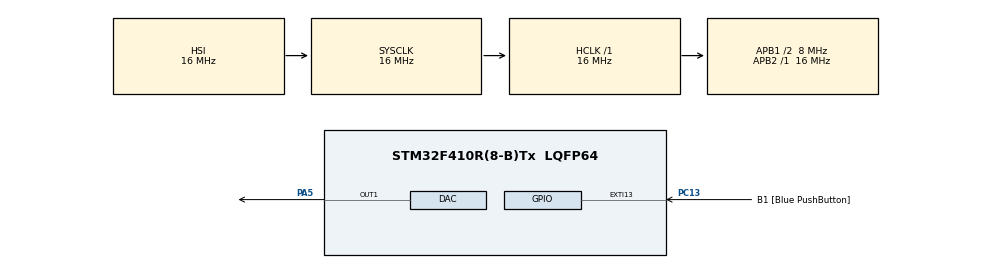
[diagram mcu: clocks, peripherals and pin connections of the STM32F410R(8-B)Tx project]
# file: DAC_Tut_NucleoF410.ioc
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DAC.DAC_Trigger=DAC_TRIGGER_T6_TRGO
Dma.DAC1.0.Direction=DMA_MEMORY_TO_PERIPH
Dma.DAC1.0.FIFOMode=DMA_FIFOMODE_DISABLE
Dma.DAC1.0.Instance=DMA1_Stream5
Dma.DAC1.0.MemDataAlignment=DMA_MDATAALIGN_HALFWORD
Dma.DAC1.0.MemInc=DMA_MINC_ENABLE
Dma.DAC1.0.Mode=DMA_CIRCULAR
Dma.DAC1.0.PeriphDataAlignment=DMA_PDATAALIGN_HALFWORD
Dma.DAC1.0.PeriphInc=DMA_PINC_DISABLE
Dma.DAC1.0.Priority=DMA_PRIORITY_LOW
Dma.Request0=DAC1
Mcu.Family=STM32F4
Mcu.Name=STM32F410R(8-B)Tx
Mcu.Package=LQFP64
NVIC.DMA1_Stream5_IRQn=true\:0\:0\:false\:false\:true\:false\:true\:true
NVIC.PriorityGroup=NVIC_PRIORITYGROUP_0
NVIC.TIM6_DAC_IRQn=true\:0\:0\:false\:false\:true\:true\:true\:true
PA13.GPIO_Label=TMS
PA13.Mode=Serial_Wire
PA13.Signal=SYS_JTMS-SWDIO
PA14.GPIO_Label=TCK
PA14.Mode=Serial_Wire
PA14.Signal=SYS_JTCK-SWCLK
PA2.GPIO_Label=USART_TX
PA2.Signal=USART2_TX
PA3.GPIO_Label=USART_RX
PA3.Signal=USART2_RX
PA5.Signal=COMP_DAC1_group
PB3.GPIO_Label=SWO
PB3.Signal=SYS_JTDO-SWO
PC13-ANTI_TAMP.GPIO_Label=B1 [Blue PushButton]
PC13-ANTI_TAMP.GPIO_ModeDefaultEXTI=GPIO_MODE_IT_FALLING
PC13-ANTI_TAMP.Signal=GPXTI13
PC14-OSC32_IN.Mode=LSE-External-Oscillator
PC14-OSC32_IN.Signal=RCC_OSC32_IN
PC15-OSC32_OUT.Mode=LSE-External-Oscillator
PC15-OSC32_OUT.Signal=RCC_OSC32_OUT
PH0\ -\ OSC_IN.Mode=HSE-External-Clock-Source
PH0\ -\ OSC_IN.Signal=RCC_OSC_IN
PH1\ -\ OSC_OUT.Mode=HSE-External-Clock-Source
PH1\ -\ OSC_OUT.Signal=RCC_OSC_OUT
ProjectManager.HeapSize=0x200
ProjectManager.StackSize=0x400
ProjectManager.TargetToolchain=STM32CubeIDE
RCC.48MHZClocksFreq_Value=336000000
RCC.AHBFreq_Value=16000000
RCC.APB1CLKDivider=RCC_HCLK_DIV2
RCC.APB1Freq_Value=8000000
RCC.APB1TimFreq_Value=16000000
RCC.APB2Freq_Value=16000000
RCC.APB2TimFreq_Value=16000000
RCC.CortexFreq_Value=16000000
RCC.FLatency-AdvancedSettings=FLASH_LATENCY_0
RCC.HCLKFreq_Value=16000000
RCC.HSE_VALUE=8000000
RCC.HSI_VALUE=16000000
RCC.PLLM=4
RCC.PLLN=336
RCC.PLLP=RCC_PLLP_DIV4
RCC.SYSCLKFreq_VALUE=16000000
RCC.VCOOutputFreq_Value=1344000000
SH.COMP_DAC1_group.0=DAC_OUT1,DAC_OUT1
TIM6.TIM_MasterOutputTrigger=TIM_TRGO_UPDATE
VP_TIM6_VS_ClockSourceINT.Mode=Enable_Timer
board=NUCLEO-F410RB

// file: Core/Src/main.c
/* USER CODE BEGIN Header */
/**
  ******************************************************************************
  * @file           : main.c
  * @brief          : Main program body
  ******************************************************************************
  * @attention
  *
  * Copyright (c) 2023 STMicroelectronics.
  * All rights reserved.
  *
  * This software is licensed under terms that can be found in the LICENSE file
  * in the root directory of this software component.
  * If no LICENSE file comes with this software, it is provided AS-IS.
  *
  ******************************************************************************
  */
/* USER CODE END Header */
#include "main.h"

/* USER CODE BEGIN Includes */
#include "math.h"

/* USER CODE END Includes */

/* USER CODE BEGIN PD */
#define PI 3.14159
#define NO_OF_SAMPLES 200
/* USER CODE END PD */

 DAC_HandleTypeDef hdac;
DMA_HandleTypeDef hdma_dac1;

TIM_HandleTypeDef htim6;

void SystemClock_Config(void);
static void MX_GPIO_Init(void);
static void MX_DMA_Init(void);
static void MX_DAC_Init(void);
static void MX_TIM6_Init(void);

int main(void)
{
  /* USER CODE BEGIN 1 */
	// Defining an array with sine wave values.
	uint16_t valuesBuffer[NO_OF_SAMPLES], value;
	for (uint16_t i = 0; i < NO_OF_SAMPLES; i++) {
		value = (uint16_t) rint( (sinf( ((2*PI)/NO_OF_SAMPLES)*i) + 1 )*2048 );
		valuesBuffer[i] = value < 4096 ? value : 4095;
	}

  /* USER CODE END 1 */

  /* MCU Configuration--------------------------------------------------------*/

  /* Reset of all peripherals, Initializes the Flash interface and the Systick. */
  HAL_Init();

  /* Configure the system clock */
  SystemClock_Config();

  /* Initialize all configured peripherals */
  MX_GPIO_Init();
  MX_DMA_Init();
  MX_DAC_Init();
  MX_TIM6_Init();
  /* USER CODE BEGIN 2 */

//  // <-- using Polling Mode -->
//  HAL_DAC_Start(&hdac, DAC_CHANNEL_1);	// for Polling Mode

  // <-- using DMA Mode -->
  HAL_TIM_Base_Start(&htim6);	// for DMA Mode
  HAL_DAC_Start_DMA(&hdac, DAC_CHANNEL_1, (uint32_t*)valuesBuffer, NO_OF_SAMPLES, DAC_ALIGN_12B_R);	// for DMA Mode

  /* USER CODE END 2 */

  /* Infinite loop */
  /* USER CODE BEGIN WHILE */
  while (1)
  {
//// <-- using Poll Mode -->
//	  for (uint16_t i = 0; i < NO_OF_SAMPLES; i++) {
//		  HAL_DAC_SetValue(&hdac, DAC_CHANNEL_1, DAC_ALIGN_12B_R, valuesBuffer[i]);
//		  HAL_Delay(1);
//	  }

    /* USER CODE END WHILE */

  }
}

void SystemClock_Config(void)
{
  RCC_OscInitTypeDef RCC_OscInitStruct = {0};
  RCC_ClkInitTypeDef RCC_ClkInitStruct = {0};

  /** Configure the main internal regulator output voltage
  */
  __HAL_RCC_PWR_CLK_ENABLE();
  __HAL_PWR_VOLTAGESCALING_CONFIG(PWR_REGULATOR_VOLTAGE_SCALE1);

  /** Initializes the RCC Oscillators according to the specified parameters
  * in the RCC_OscInitTypeDef structure.
  */
  RCC_OscInitStruct.OscillatorType = RCC_OSCILLATORTYPE_HSI;
  RCC_OscInitStruct.HSIState = RCC_HSI_ON;
  RCC_OscInitStruct.HSICalibrationValue = RCC_HSICALIBRATION_DEFAULT;
  RCC_OscInitStruct.PLL.PLLState = RCC_PLL_NONE;
  if (HAL_RCC_OscConfig(&RCC_OscInitStruct) != HAL_OK)
  {
    Error_Handler();
  }

  /** Initializes the CPU, AHB and APB buses clocks
  */
  RCC_ClkInitStruct.ClockType = RCC_CLOCKTYPE_HCLK|RCC_CLOCKTYPE_SYSCLK
                              |RCC_CLOCKTYPE_PCLK1|RCC_CLOCKTYPE_PCLK2;
  RCC_ClkInitStruct.SYSCLKSource = RCC_SYSCLKSOURCE_HSI;
  RCC_ClkInitStruct.AHBCLKDivider = RCC_SYSCLK_DIV1;
  RCC_ClkInitStruct.APB1CLKDivider = RCC_HCLK_DIV2;
  RCC_ClkInitStruct.APB2CLKDivider = RCC_HCLK_DIV1;

  if (HAL_RCC_ClockConfig(&RCC_ClkInitStruct, FLASH_LATENCY_0) != HAL_OK)
  {
    Error_Handler();
  }
}

static void MX_DAC_Init(void)
{

  DAC_ChannelConfTypeDef sConfig = {0};

  /** DAC Initialization
  */
  hdac.Instance = DAC;
  if (HAL_DAC_Init(&hdac) != HAL_OK)
  {
    Error_Handler();
  }

  /** DAC channel OUT1 config
  */
  sConfig.DAC_Trigger = DAC_TRIGGER_T6_TRGO;
  sConfig.DAC_OutputBuffer = DAC_OUTPUTBUFFER_ENABLE;
  if (HAL_DAC_ConfigChannel(&hdac, &sConfig, DAC_CHANNEL_1) != HAL_OK)
  {
    Error_Handler();
  }

}

static void MX_TIM6_Init(void)
{

  TIM_MasterConfigTypeDef sMasterConfig = {0};

  htim6.Instance = TIM6;
  htim6.Init.Prescaler = 0;
  htim6.Init.CounterMode = TIM_COUNTERMODE_UP;
  htim6.Init.Period = 65535;
  htim6.Init.AutoReloadPreload = TIM_AUTORELOAD_PRELOAD_DISABLE;
  if (HAL_TIM_Base_Init(&htim6) != HAL_OK)
  {
    Error_Handler();
  }
  sMasterConfig.MasterOutputTrigger = TIM_TRGO_UPDATE;
  sMasterConfig.MasterSlaveMode = TIM_MASTERSLAVEMODE_DISABLE;
  if (HAL_TIMEx_MasterConfigSynchronization(&htim6, &sMasterConfig) != HAL_OK)
  {
    Error_Handler();
  }

}

static void MX_DMA_Init(void)
{

  /* DMA controller clock enable */
  __HAL_RCC_DMA1_CLK_ENABLE();

  /* DMA interrupt init */
  /* DMA1_Stream5_IRQn interrupt configuration */
  HAL_NVIC_SetPriority(DMA1_Stream5_IRQn, 0, 0);
  HAL_NVIC_EnableIRQ(DMA1_Stream5_IRQn);

}

static void MX_GPIO_Init(void)
{
  GPIO_InitTypeDef GPIO_InitStruct = {0};

  /* GPIO Ports Clock Enable */
  __HAL_RCC_GPIOC_CLK_ENABLE();
  __HAL_RCC_GPIOH_CLK_ENABLE();
  __HAL_RCC_GPIOA_CLK_ENABLE();
  __HAL_RCC_GPIOB_CLK_ENABLE();

  /*Configure GPIO pin : B1_Pin */
  GPIO_InitStruct.Pin = B1_Pin;
  GPIO_InitStruct.Mode = GPIO_MODE_IT_FALLING;
  GPIO_InitStruct.Pull = GPIO_NOPULL;
  HAL_GPIO_Init(B1_GPIO_Port, &GPIO_InitStruct);

  /*Configure GPIO pins : USART_TX_Pin USART_RX_Pin */
  GPIO_InitStruct.Pin = USART_TX_Pin|USART_RX_Pin;
  GPIO_InitStruct.Mode = GPIO_MODE_AF_PP;
  GPIO_InitStruct.Pull = GPIO_NOPULL;
  GPIO_InitStruct.Speed = GPIO_SPEED_FREQ_VERY_HIGH;
  GPIO_InitStruct.Alternate = GPIO_AF7_USART2;
  HAL_GPIO_Init(GPIOA, &GPIO_InitStruct);

}

void Error_Handler(void)
{
  __disable_irq();
  while (1)
  {
  }
}
